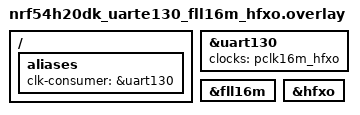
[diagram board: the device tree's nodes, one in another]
/*
 * Case: nRF54H20, uarte130 as the consumer, 16 MHz clock generated by fll16m switched to its
 * HFXO-bypass source for accuracy.
 *
 * uarte130 is only used to carry the clock state; the sample does not operate the UARTE. The
 * pclk16m_hfxo state runs at 16 MHz and names fll16m as its producer with
 * producer-accuracy-ppm = <1> (NRF_CLOCK_CONTROL_ACCURACY_MAX), so the sample requests fll16m
 * with that specification and it selects the HFXO-bypass source (starting the HFXO).
 */
/ {
	aliases {
		clk-consumer = &uart130;
	};
};

&uart130 {
	clocks = <&pclk16m_hfxo>;
};

&fll16m {
	status = "okay";
};

&hfxo {
	status = "okay";
};
